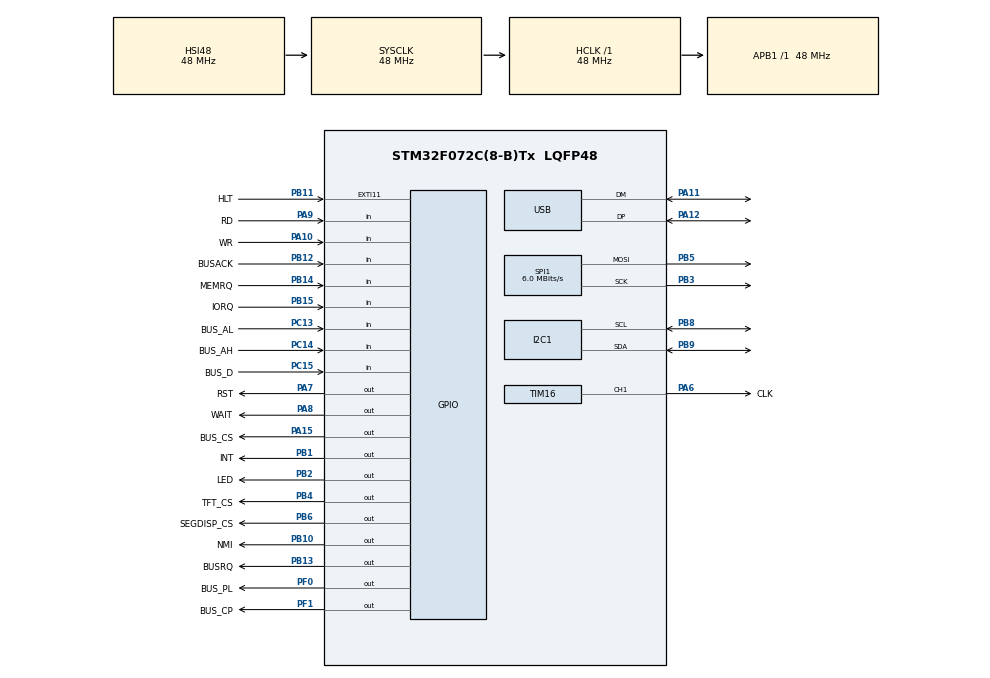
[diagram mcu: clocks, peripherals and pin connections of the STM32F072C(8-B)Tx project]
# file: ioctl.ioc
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Mcu.Family=STM32F0
USB_DEVICE.CLASS_NAME_FS=CDC
SPI1.VirtualType=VM_MASTER
NVIC.USB_IRQn=true\:0\:0\:false\:false\:true\:false\:true
PB14.GPIO_Label=MEMRQ
PA11.Mode=Device
PB6.GPIO_Label=SEGDISP_CS
PA6.GPIO_Label=CLK
PC13.GPIO_Label=BUS_AL
PB13.GPIO_Label=BUSRQ
PB11.Signal=GPXTI11
PB13.Signal=GPIO_Output
PB15.Signal=GPIO_Input
PC15-OSC32_OUT.GPIO_Label=BUS_D
RCC.SYSCLKSource=RCC_SYSCLKSOURCE_HSI48
ProjectManager.StackSize=0x400
NVIC.I2C1_IRQn=true\:0\:0\:false\:false\:true\:true\:true
USB_DEVICE.MANUFACTURER_STRING=sens
PA15.GPIO_Label=BUS_CS
PA12.Signal=USB_DP
SPI1.Direction=SPI_DIRECTION_2LINES
RCC.HCLKFreq_Value=48000000
PB6.Signal=GPIO_Output
SPI1.CalculateBaudRate=6.0 MBits/s
RCC.AHBFreq_Value=48000000
PF0-OSC_IN.GPIO_Label=BUS_PL
PB2.Signal=GPIO_Output
PB3.Mode=TX_Only_Simplex_Unidirect_Master
PB12.GPIO_Label=BUSACK
PB1.GPIO_Label=INT
PB5.Mode=TX_Only_Simplex_Unidirect_Master
SPI1.DataSize=SPI_DATASIZE_8BIT
PA10.GPIO_Label=WR
PA8.Signal=GPIO_Output
Mcu.Package=LQFP48
PB9.Signal=I2C1_SDA
PA6.Signal=S_TIM16_CH1
PB1.Signal=GPIO_Output
PB11.GPIO_ModeDefaultEXTI=GPIO_MODE_IT_FALLING
PA10.Signal=GPIO_Input
PA15.Signal=GPIO_Output
RCC.APB1TimFreq_Value=48000000
PC14-OSC32_IN.GPIO_Label=BUS_AH
SPI1.BaudRatePrescaler=SPI_BAUDRATEPRESCALER_8
PF1-OSC_OUT.Signal=GPIO_Output
NVIC.EXTI4_15_IRQn=true\:0\:0\:false\:false\:true\:true\:true
PB4.Signal=GPIO_Output
USB_DEVICE.VirtualModeFS=Cdc_FS
PC13.Signal=GPIO_Input
PA9.GPIO_Label=RD
PB11.GPIO_Label=HLT
SH.S_TIM16_CH1.0=TIM16_CH1,PWM Generation1 CH1
VP_TIM16_VS_ClockSourceINT.Mode=Enable_Timer
NVIC.TIM16_IRQn=true\:0\:0\:false\:false\:true\:true\:true
PC14-OSC32_IN.Signal=GPIO_Input
TIM16.Channel=TIM_CHANNEL_1
PA8.GPIO_Label=WAIT
ProjectManager.TargetToolchain=Makefile
USB_DEVICE.PRODUCT_STRING_CDC_FS=uz8021 IOCTL
PB10.GPIO_Label=NMI
VP_USB_DEVICE_VS_USB_DEVICE_CDC_FS.Mode=CDC_FS
PB9.Mode=I2C
PA9.Signal=GPIO_Input
PC15-OSC32_OUT.Signal=GPIO_Input
PB10.Signal=GPIO_Output
PB14.Signal=GPIO_Input
board=custom
NVIC.SPI1_IRQn=true\:0\:0\:false\:false\:true\:true\:true
PB4.GPIO_Label=TFT_CS
PB15.GPIO_Label=IORQ
SPI1.Mode=SPI_MODE_MASTER
PF1-OSC_OUT.GPIO_Label=BUS_CP
Mcu.Name=STM32F072C(8-B)Tx
PB3.Signal=SPI1_SCK
RCC.SYSCLKFreq_VALUE=48000000
PB5.Signal=SPI1_MOSI
PA7.GPIO_Label=RST
PA12.Mode=Device
PA11.Signal=USB_DM
PB2.GPIO_Label=LED
ProjectManager.HeapSize=0x200
PB8.Mode=I2C
PB8.Signal=I2C1_SCL
PF0-OSC_IN.Signal=GPIO_Output
RCC.APB1Freq_Value=48000000
USB_DEVICE.VirtualMode=Cdc
PB12.Signal=GPIO_Input
PA7.Signal=GPIO_Output

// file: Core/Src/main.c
/* USER CODE BEGIN Header */
/**
  ******************************************************************************
  * @file           : main.c
  * @brief          : Main program body
  ******************************************************************************
  * @attention
  *
  * <h2><center>&copy; Copyright (c) 2021 STMicroelectronics.
  * All rights reserved.</center></h2>
  *
  * This software component is licensed by ST under Ultimate Liberty license
  * SLA0044, the "License"; You may not use this file except in compliance with
  * the License. You may obtain a copy of the License at:
  *                             www.st.com/SLA0044
  *
  ******************************************************************************
  */
/* USER CODE END Header */
#include "main.h"
#include "i2c.h"
#include "spi.h"
#include "tim.h"
#include "usb_device.h"
#include "gpio.h"

/* USER CODE BEGIN Includes */

#include "usbd_cdc_if.h"
#include "ioctl.h"

/* USER CODE END Includes */

void SystemClock_Config(void);
/* USER CODE BEGIN PFP */

void HAL_TIM_PWM_PulseFinishedCallback(TIM_HandleTypeDef *htim) {
  if (htim == &htim16) {
    ioctl_clk_pulse_callback();
  }
}

/* USER CODE END PFP */

int main(void)
{

  /* MCU Configuration--------------------------------------------------------*/

  /* Reset of all peripherals, Initializes the Flash interface and the Systick. */
  HAL_Init();

  /* Configure the system clock */
  SystemClock_Config();

  /* Initialize all configured peripherals */
  MX_GPIO_Init();
  MX_USB_DEVICE_Init();
  MX_I2C1_Init();
  MX_SPI1_Init();
  MX_TIM16_Init();
  /* USER CODE BEGIN 2 */

  HAL_TIM_Base_Start(&htim16);
  HAL_TIM_PWM_Start_IT(&htim16, TIM_CHANNEL_1);
  ioctl_init();
  static uint32_t led_debounce = 0;

  /* USER CODE END 2 */

  /* Infinite loop */
  /* USER CODE BEGIN WHILE */
  while (1)
  {
    if (ioctl_cmd_available()) {
      ioctl_cmd_handle();
    }

    if (HAL_GetTick() - led_debounce > 100) {
      HAL_GPIO_TogglePin(LED_GPIO_Port, LED_Pin);
      led_debounce = HAL_GetTick();
    }

    /* USER CODE END WHILE */

  }
}

void SystemClock_Config(void)
{
  RCC_OscInitTypeDef RCC_OscInitStruct = {0};
  RCC_ClkInitTypeDef RCC_ClkInitStruct = {0};
  RCC_PeriphCLKInitTypeDef PeriphClkInit = {0};

  /** Initializes the RCC Oscillators according to the specified parameters
  * in the RCC_OscInitTypeDef structure.
  */
  RCC_OscInitStruct.OscillatorType = RCC_OSCILLATORTYPE_HSI|RCC_OSCILLATORTYPE_HSI48;
  RCC_OscInitStruct.HSIState = RCC_HSI_ON;
  RCC_OscInitStruct.HSI48State = RCC_HSI48_ON;
  RCC_OscInitStruct.HSICalibrationValue = RCC_HSICALIBRATION_DEFAULT;
  RCC_OscInitStruct.PLL.PLLState = RCC_PLL_NONE;
  if (HAL_RCC_OscConfig(&RCC_OscInitStruct) != HAL_OK)
  {
    Error_Handler();
  }
  /** Initializes the CPU, AHB and APB buses clocks
  */
  RCC_ClkInitStruct.ClockType = RCC_CLOCKTYPE_HCLK|RCC_CLOCKTYPE_SYSCLK
                              |RCC_CLOCKTYPE_PCLK1;
  RCC_ClkInitStruct.SYSCLKSource = RCC_SYSCLKSOURCE_HSI48;
  RCC_ClkInitStruct.AHBCLKDivider = RCC_SYSCLK_DIV1;
  RCC_ClkInitStruct.APB1CLKDivider = RCC_HCLK_DIV1;

  if (HAL_RCC_ClockConfig(&RCC_ClkInitStruct, FLASH_LATENCY_1) != HAL_OK)
  {
    Error_Handler();
  }
  PeriphClkInit.PeriphClockSelection = RCC_PERIPHCLK_USB|RCC_PERIPHCLK_I2C1;
  PeriphClkInit.I2c1ClockSelection = RCC_I2C1CLKSOURCE_HSI;
  PeriphClkInit.UsbClockSelection = RCC_USBCLKSOURCE_HSI48;

  if (HAL_RCCEx_PeriphCLKConfig(&PeriphClkInit) != HAL_OK)
  {
    Error_Handler();
  }
}

void Error_Handler(void)
{
}

/************************ (C) COPYRIGHT STMicroelectronics *****END OF FILE****/
